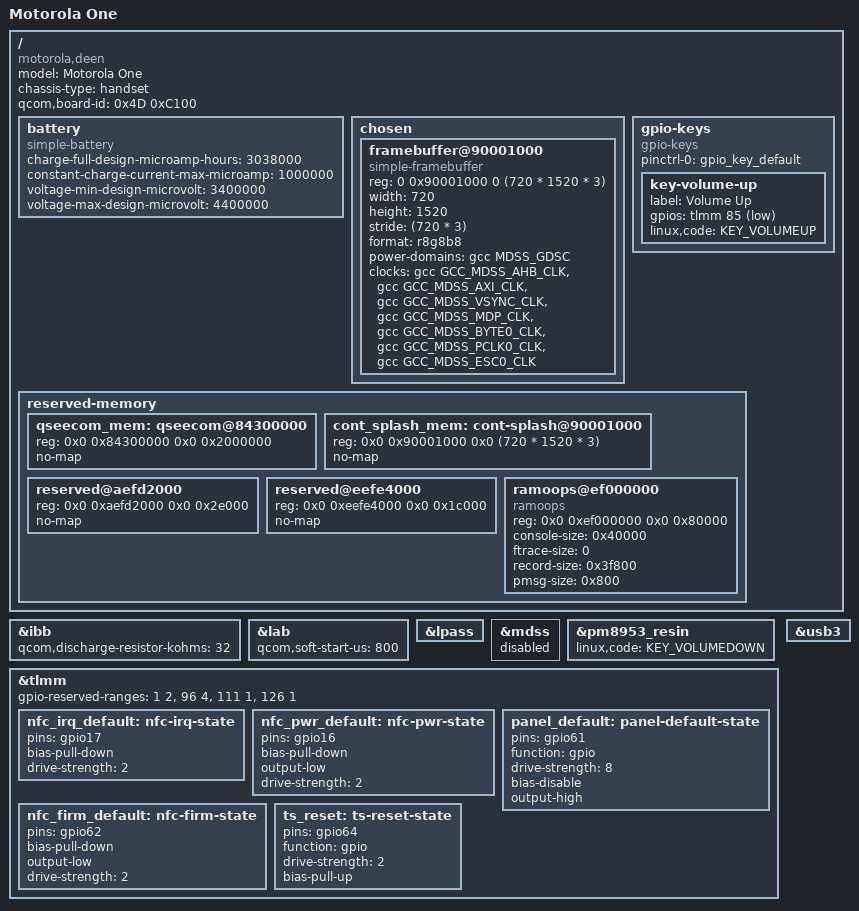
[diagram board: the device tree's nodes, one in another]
// SPDX-License-Identifier: BSD-3-Clause
/*
 * Copyright (c) 2022, Sireesh Kodali
 */
/dts-v1/;

#include "msm8953.dtsi"
#include "pm8953.dtsi"
#include "pmi8950.dtsi"

/delete-node/ &cont_splash_mem;
/delete-node/ &qseecom_mem;

/ {
	model = "Motorola One";
	compatible = "motorola,deen", "qcom,msm8953";
	chassis-type = "handset";
	qcom,board-id = <0x4D 0xC100>;

	battery: battery {
		compatible = "simple-battery";

		charge-full-design-microamp-hours = <3038000>;
		constant-charge-current-max-microamp = <1000000>;
		voltage-min-design-microvolt = <3400000>;
		voltage-max-design-microvolt = <4400000>;
	};

	chosen {
		#address-cells = <2>;
		#size-cells = <2>;
		ranges;

		framebuffer@90001000 {
			compatible = "simple-framebuffer";
			reg = <0 0x90001000 0 (720 * 1520 * 3)>;
			width = <720>;
			height = <1520>;
			stride = <(720 * 3)>;
			format = "r8g8b8";

			power-domains = <&gcc MDSS_GDSC>;

			clocks = <&gcc GCC_MDSS_AHB_CLK>,
				 <&gcc GCC_MDSS_AXI_CLK>,
				 <&gcc GCC_MDSS_VSYNC_CLK>,
				 <&gcc GCC_MDSS_MDP_CLK>,
				 <&gcc GCC_MDSS_BYTE0_CLK>,
				 <&gcc GCC_MDSS_PCLK0_CLK>,
				 <&gcc GCC_MDSS_ESC0_CLK>;
		};
	};

	gpio-keys {
		compatible = "gpio-keys";

		pinctrl-names = "default";
		pinctrl-0 = <&gpio_key_default>;

		key-volume-up {
			label = "Volume Up";
			gpios = <&tlmm 85 GPIO_ACTIVE_LOW>;
			linux,code = <KEY_VOLUMEUP>;
		};
	};

	reserved-memory {
		qseecom_mem: qseecom@84300000 {
			reg = <0x0 0x84300000 0x0 0x2000000>;
			no-map;
		};

		cont_splash_mem: cont-splash@90001000 {
			reg = <0x0 0x90001000 0x0 (720 * 1520 * 3)>;
			no-map;
		};

		reserved@aefd2000 {
			reg = <0x0 0xaefd2000 0x0 0x2e000>;
			no-map;
		};

		reserved@eefe4000 {
			reg = <0x0 0xeefe4000 0x0 0x1c000>;
			no-map;
		};

		ramoops@ef000000 {
			compatible = "ramoops";
			reg = <0x0 0xef000000 0x0 0x80000>;
			console-size = <0x40000>;
			ftrace-size = <0>;
			record-size = <0x3f800>;
			pmsg-size = <0x800>;
		};
	};
};

&ibb {
	qcom,discharge-resistor-kohms = <32>;
};

&lab {
	qcom,soft-start-us = <800>;
};

&lpass {
	status = "okay";
};

&mdss {
	status = "disabled";
};

&pm8953_resin {
	linux,code = <KEY_VOLUMEDOWN>;
	status = "okay";
};

&tlmm {
	gpio-reserved-ranges = <1 2>, <96 4>, <111 1>, <126 1>;

	nfc_irq_default: nfc-irq-state {
		pins = "gpio17";
		bias-pull-down;
		drive-strength = <2>;
	};

	nfc_pwr_default: nfc-pwr-state {
		pins = "gpio16";
		bias-pull-down;
		output-low;
		drive-strength = <2>;
	};

	panel_default: panel-default-state {
		pins = "gpio61";
		function = "gpio";
		drive-strength = <8>;
		bias-disable;
		output-high;
	};

	nfc_firm_default: nfc-firm-state {
		pins = "gpio62";
		bias-pull-down;
		output-low;
		drive-strength = <2>;
	};

	ts_reset: ts-reset-state {
		pins = "gpio64";
		function = "gpio";
		drive-strength = <2>;
		bias-pull-up;
	};
};

&usb3 {
	status = "okay";
};

